AUTOSAR XML (schema 4-1-3)
standard types defined: boolean, uint8
package /UAES/ASW/CompuMethods
  compu method CM_boolean: 0=FALSE, 1=TRUE
package /UAES/ASW/DataConstrs
  range DC_boolean: raw 0..1
  range DC_uint8: raw 0..255
package /UAES/ASW/DataTypeMappingSets
  data type mapping set DTMS_Lock_ComCnvTx
package /UAES/ASW/PortInterfaces
  58 x sender receiver interface:
    ComTx_bLCK_ExterSwOpenFillerCapReq: invalidation-policy{data-element=ComTx_bLCK_ExterSwOpenFillerCapReq/Val, handle-invalid=DONT-INVALIDATE}
      data Val: sw-calibration-access=READ-ONLY, type=boolean
    ComTx_bLCK_FillerCapASt: invalidation-policy{data-element=ComTx_bLCK_FillerCapASt/Val, handle-invalid=DONT-INVALIDATE}
      data Val: sw-calibration-access=READ-ONLY, type=boolean
    ComTx_bLCK_FillerCapBSt: invalidation-policy{data-element=ComTx_bLCK_FillerCapBSt/Val, handle-invalid=DONT-INVALIDATE}
      data Val: sw-calibration-access=READ-ONLY, type=boolean
    ComTx_bLCK_RearLeftChildSaftyLockSt: invalidation-policy{data-element=ComTx_bLCK_RearLeftChildSaftyLockSt/Val, handle-invalid=DONT-INVALIDATE}
      data Val: sw-calibration-access=READ-ONLY, type=boolean
    ComTx_bLCK_RearLeftDoorAjarSt: invalidation-policy{data-element=ComTx_bLCK_RearLeftDoorAjarSt/Val, handle-invalid=DONT-INVALIDATE}
      data Val: sw-calibration-access=READ-ONLY, type=boolean
    ComTx_bLCK_RearLeftDoorLockSt: invalidation-policy{data-element=ComTx_bLCK_RearLeftDoorLockSt/Val, handle-invalid=DONT-INVALIDATE}
      data Val: sw-calibration-access=READ-ONLY, type=boolean
    ComTx_bLCK_RearLeftDoorOpenSt: invalidation-policy{data-element=ComTx_bLCK_RearLeftDoorOpenSt/Val, handle-invalid=DONT-INVALIDATE}
      data Val: sw-calibration-access=READ-ONLY, type=boolean
    ComTx_bLCK_RearLeftPowerReleaseFailedRemind: invalidation-policy{data-element=ComTx_bLCK_RearLeftPowerReleaseFailedRemind/Val, handle-invalid=DONT-INVALIDATE}
      data Val: sw-calibration-access=READ-ONLY, type=boolean
    ComTx_bLCK_RearRightChildSaftyLockSt: invalidation-policy{data-element=ComTx_bLCK_RearRightChildSaftyLockSt/Val, handle-invalid=DONT-INVALIDATE}
      data Val: sw-calibration-access=READ-ONLY, type=boolean
    ComTx_bLCK_RearRightDoorAjarSt: invalidation-policy{data-element=ComTx_bLCK_RearRightDoorAjarSt/Val, handle-invalid=DONT-INVALIDATE}
      data Val: sw-calibration-access=READ-ONLY, type=boolean
    ComTx_bLCK_RearRightDoorLockSt: invalidation-policy{data-element=ComTx_bLCK_RearRightDoorLockSt/Val, handle-invalid=DONT-INVALIDATE}
      data Val: sw-calibration-access=READ-ONLY, type=boolean
    ComTx_bLCK_RearRightDoorOpenSt: invalidation-policy{data-element=ComTx_bLCK_RearRightDoorOpenSt/Val, handle-invalid=DONT-INVALIDATE}
      data Val: sw-calibration-access=READ-ONLY, type=boolean
    ComTx_bLCK_RearRightPowerReleaseFailedRemind: invalidation-policy{data-element=ComTx_bLCK_RearRightPowerReleaseFailedRemind/Val, handle-invalid=DONT-INVALIDATE}
      data Val: sw-calibration-access=READ-ONLY, type=boolean
    ComTx_bLCK_TrunkAjarSt: invalidation-policy{data-element=ComTx_bLCK_TrunkAjarSt/Val, handle-invalid=DONT-INVALIDATE}
      data Val: sw-calibration-access=READ-ONLY, type=boolean
    ComTx_bUINM_RearLeftPowerReleaseFaultSt: invalidation-policy{data-element=ComTx_bUINM_RearLeftPowerReleaseFaultSt/Val, handle-invalid=DONT-INVALIDATE}
      data Val: sw-calibration-access=READ-ONLY, type=boolean
    ComTx_bUINM_RearLeftPowerReleaseReq: invalidation-policy{data-element=ComTx_bUINM_RearLeftPowerReleaseReq/Val, handle-invalid=DONT-INVALIDATE}
      data Val: sw-calibration-access=READ-ONLY, type=boolean
    ComTx_bUINM_RearRightPowerReleaseFaultSt: invalidation-policy{data-element=ComTx_bUINM_RearRightPowerReleaseFaultSt/Val, handle-invalid=DONT-INVALIDATE}
      data Val: sw-calibration-access=READ-ONLY, type=boolean
    ComTx_bUINM_RearRightPowerReleaseReq: invalidation-policy{data-element=ComTx_bUINM_RearRightPowerReleaseReq/Val, handle-invalid=DONT-INVALIDATE}
      data Val: sw-calibration-access=READ-ONLY, type=boolean
    ComTx_u8LCK_FillerCapAction: invalidation-policy{data-element=ComTx_u8LCK_FillerCapAction/Val, handle-invalid=DONT-INVALIDATE}
      data Val: sw-calibration-access=READ-ONLY, type=uint8
    ComTx_u8LCK_FillerCapLock_AAction: invalidation-policy{data-element=ComTx_u8LCK_FillerCapLock_AAction/Val, handle-invalid=DONT-INVALIDATE}
      data Val: sw-calibration-access=READ-ONLY, type=uint8
    ComTx_u8LCK_FillerCapLock_BAction: invalidation-policy{data-element=ComTx_u8LCK_FillerCapLock_BAction/Val, handle-invalid=DONT-INVALIDATE}
      data Val: sw-calibration-access=READ-ONLY, type=uint8
    ComTx_u8LCK_PowerFillerCapAngle: invalidation-policy{data-element=ComTx_u8LCK_PowerFillerCapAngle/Val, handle-invalid=DONT-INVALIDATE}
      data Val: sw-calibration-access=READ-ONLY, type=uint8
    ComTx_u8LCK_RearLeftChildSaftyLockAction: invalidation-policy{data-element=ComTx_u8LCK_RearLeftChildSaftyLockAction/Val, handle-invalid=DONT-INVALIDATE}
      data Val: sw-calibration-access=READ-ONLY, type=uint8
    ComTx_u8LCK_RearLeftDoorLockAction: invalidation-policy{data-element=ComTx_u8LCK_RearLeftDoorLockAction/Val, handle-invalid=DONT-INVALIDATE}
      data Val: sw-calibration-access=READ-ONLY, type=uint8
    ComTx_u8LCK_RearLeftPowerDoorAction: invalidation-policy{data-element=ComTx_u8LCK_RearLeftPowerDoorAction/Val, handle-invalid=DONT-INVALIDATE}
      data Val: sw-calibration-access=READ-ONLY, type=uint8
    ComTx_u8LCK_RearRightChildSaftyLockAction: invalidation-policy{data-element=ComTx_u8LCK_RearRightChildSaftyLockAction/Val, handle-invalid=DONT-INVALIDATE}
      data Val: sw-calibration-access=READ-ONLY, type=uint8
    ComTx_u8LCK_RearRightDoorLockAction: invalidation-policy{data-element=ComTx_u8LCK_RearRightDoorLockAction/Val, handle-invalid=DONT-INVALIDATE}
      data Val: sw-calibration-access=READ-ONLY, type=uint8
    ComTx_u8LCK_RearRightPowerDoorAction: invalidation-policy{data-element=ComTx_u8LCK_RearRightPowerDoorAction/Val, handle-invalid=DONT-INVALIDATE}
      data Val: sw-calibration-access=READ-ONLY, type=uint8
    ComTx_u8LCK_TrunkLockAction: invalidation-policy{data-element=ComTx_u8LCK_TrunkLockAction/Val, handle-invalid=DONT-INVALIDATE}
      data Val: sw-calibration-access=READ-ONLY, type=uint8
    gLOC_bLCK_ExterSwOpenFillerCapReq: invalidation-policy{data-element=gLOC_bLCK_ExterSwOpenFillerCapReq/Val, handle-invalid=DONT-INVALIDATE}
      data Val: sw-calibration-access=READ-ONLY, type=boolean
    gLOC_bLCK_RearLeftChildSaftyLockSt: invalidation-policy{data-element=gLOC_bLCK_RearLeftChildSaftyLockSt/Val, handle-invalid=DONT-INVALIDATE}
      data Val: sw-calibration-access=READ-ONLY, type=boolean
    gLOC_bLCK_RearLeftDoorAjarSt: invalidation-policy{data-element=gLOC_bLCK_RearLeftDoorAjarSt/Val, handle-invalid=DONT-INVALIDATE}
      data Val: sw-calibration-access=READ-ONLY, type=boolean
    gLOC_bLCK_RearLeftDoorLockSt: invalidation-policy{data-element=gLOC_bLCK_RearLeftDoorLockSt/Val, handle-invalid=DONT-INVALIDATE}
      data Val: sw-calibration-access=READ-ONLY, type=boolean
    gLOC_bLCK_RearLeftDoorOpenSt: invalidation-policy{data-element=gLOC_bLCK_RearLeftDoorOpenSt/Val, handle-invalid=DONT-INVALIDATE}
      data Val: sw-calibration-access=READ-ONLY, type=boolean
    gLOC_bLCK_RearRightChildSaftyLockSt: invalidation-policy{data-element=gLOC_bLCK_RearRightChildSaftyLockSt/Val, handle-invalid=DONT-INVALIDATE}
      data Val: sw-calibration-access=READ-ONLY, type=boolean
    gLOC_bLCK_RearRightDoorAjarSt: invalidation-policy{data-element=gLOC_bLCK_RearRightDoorAjarSt/Val, handle-invalid=DONT-INVALIDATE}
      data Val: sw-calibration-access=READ-ONLY, type=boolean
    gLOC_bLCK_RearRightDoorLockSt: invalidation-policy{data-element=gLOC_bLCK_RearRightDoorLockSt/Val, handle-invalid=DONT-INVALIDATE}
      data Val: sw-calibration-access=READ-ONLY, type=boolean
    gLOC_bLCK_RearRightDoorOpenSt: invalidation-policy{data-element=gLOC_bLCK_RearRightDoorOpenSt/Val, handle-invalid=DONT-INVALIDATE}
      data Val: sw-calibration-access=READ-ONLY, type=boolean
    gLOC_bLCK_TrunkAjarSt: invalidation-policy{data-element=gLOC_bLCK_TrunkAjarSt/Val, handle-invalid=DONT-INVALIDATE}
      data Val: sw-calibration-access=READ-ONLY, type=boolean
    gLOC_bUINM_RearLeftPowerReleaseReq: invalidation-policy{data-element=gLOC_bUINM_RearLeftPowerReleaseReq/Val, handle-invalid=DONT-INVALIDATE}
      data Val: sw-calibration-access=READ-ONLY, type=boolean
    gLOC_bUINM_RearRightPowerReleaseReq: invalidation-policy{data-element=gLOC_bUINM_RearRightPowerReleaseReq/Val, handle-invalid=DONT-INVALIDATE}
      data Val: sw-calibration-access=READ-ONLY, type=boolean
    gLOC_u8LCK_FillerCapAction: invalidation-policy{data-element=gLOC_u8LCK_FillerCapAction/Val, handle-invalid=DONT-INVALIDATE}
      data Val: sw-calibration-access=READ-ONLY, type=uint8
    gLOC_u8LCK_FillerCapAngle: invalidation-policy{data-element=gLOC_u8LCK_FillerCapAngle/Val, handle-invalid=DONT-INVALIDATE}
      data Val: sw-calibration-access=READ-ONLY, type=uint8
    gLOC_u8LCK_FillerCapLock_AAction: invalidation-policy{data-element=gLOC_u8LCK_FillerCapLock_AAction/Val, handle-invalid=DONT-INVALIDATE}
      data Val: sw-calibration-access=READ-ONLY, type=uint8
    gLOC_u8LCK_FillerCapLock_BAction: invalidation-policy{data-element=gLOC_u8LCK_FillerCapLock_BAction/Val, handle-invalid=DONT-INVALIDATE}
      data Val: sw-calibration-access=READ-ONLY, type=uint8
    gLOC_u8LCK_RearLeftChildSaftyLockAction: invalidation-policy{data-element=gLOC_u8LCK_RearLeftChildSaftyLockAction/Val, handle-invalid=DONT-INVALIDATE}
      data Val: sw-calibration-access=READ-ONLY, type=uint8
    gLOC_u8LCK_RearLeftDoorLockAction: invalidation-policy{data-element=gLOC_u8LCK_RearLeftDoorLockAction/Val, handle-invalid=DONT-INVALIDATE}
      data Val: sw-calibration-access=READ-ONLY, type=uint8
    gLOC_u8LCK_RearLeftPowerDoorAction: invalidation-policy{data-element=gLOC_u8LCK_RearLeftPowerDoorAction/Val, handle-invalid=DONT-INVALIDATE}
      data Val: sw-calibration-access=READ-ONLY, type=uint8
    gLOC_u8LCK_RearRightChildSaftyLockAction: invalidation-policy{data-element=gLOC_u8LCK_RearRightChildSaftyLockAction/Val, handle-invalid=DONT-INVALIDATE}
      data Val: sw-calibration-access=READ-ONLY, type=uint8
    gLOC_u8LCK_RearRightDoorLockAction: invalidation-policy{data-element=gLOC_u8LCK_RearRightDoorLockAction/Val, handle-invalid=DONT-INVALIDATE}
      data Val: sw-calibration-access=READ-ONLY, type=uint8
    gLOC_u8LCK_RearRightPowerDoorAction: invalidation-policy{data-element=gLOC_u8LCK_RearRightPowerDoorAction/Val, handle-invalid=DONT-INVALIDATE}
      data Val: sw-calibration-access=READ-ONLY, type=uint8
    gLOC_u8LCK_TrunkLockAction: invalidation-policy{data-element=gLOC_u8LCK_TrunkLockAction/Val, handle-invalid=DONT-INVALIDATE}
      data Val: sw-calibration-access=READ-ONLY, type=uint8
    gLock_bLCK_FillerCapASt: invalidation-policy{data-element=gLock_bLCK_FillerCapASt/Val, handle-invalid=DONT-INVALIDATE}
      data Val: sw-calibration-access=READ-ONLY, type=boolean
    gLock_bLCK_FillerCapBSt: invalidation-policy{data-element=gLock_bLCK_FillerCapBSt/Val, handle-invalid=DONT-INVALIDATE}
      data Val: sw-calibration-access=READ-ONLY, type=boolean
    gLock_bLCK_RearLeftPowerReleaseFailedRemind: invalidation-policy{data-element=gLock_bLCK_RearLeftPowerReleaseFailedRemind/Val, handle-invalid=DONT-INVALIDATE}
      data Val: sw-calibration-access=READ-ONLY, type=boolean
    gLock_bLCK_RearRightPowerReleaseFailedRemind: invalidation-policy{data-element=gLock_bLCK_RearRightPowerReleaseFailedRemind/Val, handle-invalid=DONT-INVALIDATE}
      data Val: sw-calibration-access=READ-ONLY, type=boolean
    gLock_bUINM_RearLeftPowerReleaseFaultSt: invalidation-policy{data-element=gLock_bUINM_RearLeftPowerReleaseFaultSt/Val, handle-invalid=DONT-INVALIDATE}
      data Val: sw-calibration-access=READ-ONLY, type=boolean
    gLock_bUINM_RearRightPowerReleaseFaultSt: invalidation-policy{data-element=gLock_bUINM_RearRightPowerReleaseFaultSt/Val, handle-invalid=DONT-INVALIDATE}
      data Val: sw-calibration-access=READ-ONLY, type=boolean
package /UAES/ASW/SwComponentTypes
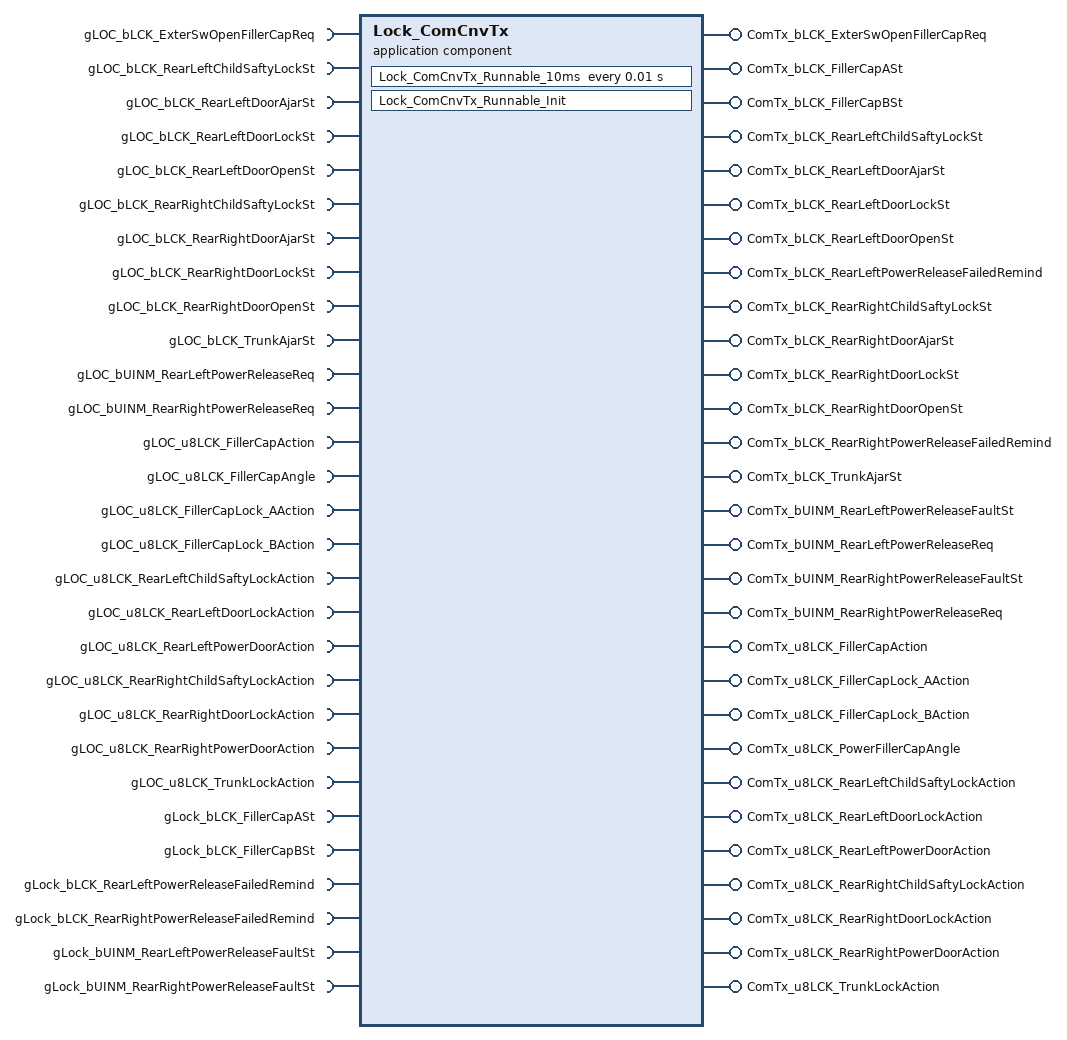
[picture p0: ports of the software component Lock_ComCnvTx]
  application sw component type Lock_ComCnvTx
    29 x provide port:
      ComTx_bLCK_ExterSwOpenFillerCapReq: nonqueued-sender-com-spec{data-element=ComTx_bLCK_ExterSwOpenFillerCapReq/Val, init-value=0}, provided-interface=ComTx_bLCK_ExterSwOpenFillerCapReq
      ComTx_bLCK_FillerCapASt: nonqueued-sender-com-spec{data-element=ComTx_bLCK_FillerCapASt/Val, init-value=0}, provided-interface=ComTx_bLCK_FillerCapASt
      ComTx_bLCK_FillerCapBSt: nonqueued-sender-com-spec{data-element=ComTx_bLCK_FillerCapBSt/Val, init-value=0}, provided-interface=ComTx_bLCK_FillerCapBSt
      ComTx_bLCK_RearLeftChildSaftyLockSt: nonqueued-sender-com-spec{data-element=ComTx_bLCK_RearLeftChildSaftyLockSt/Val, init-value=0}, provided-interface=ComTx_bLCK_RearLeftChildSaftyLockSt
      ComTx_bLCK_RearLeftDoorAjarSt: nonqueued-sender-com-spec{data-element=ComTx_bLCK_RearLeftDoorAjarSt/Val, init-value=0}, provided-interface=ComTx_bLCK_RearLeftDoorAjarSt
      ComTx_bLCK_RearLeftDoorLockSt: nonqueued-sender-com-spec{data-element=ComTx_bLCK_RearLeftDoorLockSt/Val, init-value=0}, provided-interface=ComTx_bLCK_RearLeftDoorLockSt
      ComTx_bLCK_RearLeftDoorOpenSt: nonqueued-sender-com-spec{data-element=ComTx_bLCK_RearLeftDoorOpenSt/Val, init-value=0}, provided-interface=ComTx_bLCK_RearLeftDoorOpenSt
      ComTx_bLCK_RearLeftPowerReleaseFailedRemind: nonqueued-sender-com-spec{data-element=ComTx_bLCK_RearLeftPowerReleaseFailedRemind/Val, init-value=0}, provided-interface=ComTx_bLCK_RearLeftPowerReleaseFailedRemind
      ComTx_bLCK_RearRightChildSaftyLockSt: nonqueued-sender-com-spec{data-element=ComTx_bLCK_RearRightChildSaftyLockSt/Val, init-value=0}, provided-interface=ComTx_bLCK_RearRightChildSaftyLockSt
      ComTx_bLCK_RearRightDoorAjarSt: nonqueued-sender-com-spec{data-element=ComTx_bLCK_RearRightDoorAjarSt/Val, init-value=0}, provided-interface=ComTx_bLCK_RearRightDoorAjarSt
      ComTx_bLCK_RearRightDoorLockSt: nonqueued-sender-com-spec{data-element=ComTx_bLCK_RearRightDoorLockSt/Val, init-value=0}, provided-interface=ComTx_bLCK_RearRightDoorLockSt
      ComTx_bLCK_RearRightDoorOpenSt: nonqueued-sender-com-spec{data-element=ComTx_bLCK_RearRightDoorOpenSt/Val, init-value=0}, provided-interface=ComTx_bLCK_RearRightDoorOpenSt
      ComTx_bLCK_RearRightPowerReleaseFailedRemind: nonqueued-sender-com-spec{data-element=ComTx_bLCK_RearRightPowerReleaseFailedRemind/Val, init-value=0}, provided-interface=ComTx_bLCK_RearRightPowerReleaseFailedRemind
      ComTx_bLCK_TrunkAjarSt: nonqueued-sender-com-spec{data-element=ComTx_bLCK_TrunkAjarSt/Val, init-value=0}, provided-interface=ComTx_bLCK_TrunkAjarSt
      ComTx_bUINM_RearLeftPowerReleaseFaultSt: nonqueued-sender-com-spec{data-element=ComTx_bUINM_RearLeftPowerReleaseFaultSt/Val, init-value=0}, provided-interface=ComTx_bUINM_RearLeftPowerReleaseFaultSt
      ComTx_bUINM_RearLeftPowerReleaseReq: nonqueued-sender-com-spec{data-element=ComTx_bUINM_RearLeftPowerReleaseReq/Val, init-value=0}, provided-interface=ComTx_bUINM_RearLeftPowerReleaseReq
      ComTx_bUINM_RearRightPowerReleaseFaultSt: nonqueued-sender-com-spec{data-element=ComTx_bUINM_RearRightPowerReleaseFaultSt/Val, init-value=0}, provided-interface=ComTx_bUINM_RearRightPowerReleaseFaultSt
      ComTx_bUINM_RearRightPowerReleaseReq: nonqueued-sender-com-spec{data-element=ComTx_bUINM_RearRightPowerReleaseReq/Val, init-value=0}, provided-interface=ComTx_bUINM_RearRightPowerReleaseReq
      ComTx_u8LCK_FillerCapAction: nonqueued-sender-com-spec{data-element=ComTx_u8LCK_FillerCapAction/Val, init-value=0}, provided-interface=ComTx_u8LCK_FillerCapAction
      ComTx_u8LCK_FillerCapLock_AAction: nonqueued-sender-com-spec{data-element=ComTx_u8LCK_FillerCapLock_AAction/Val, init-value=0}, provided-interface=ComTx_u8LCK_FillerCapLock_AAction
      ComTx_u8LCK_FillerCapLock_BAction: nonqueued-sender-com-spec{data-element=ComTx_u8LCK_FillerCapLock_BAction/Val, init-value=0}, provided-interface=ComTx_u8LCK_FillerCapLock_BAction
      ComTx_u8LCK_PowerFillerCapAngle: nonqueued-sender-com-spec{data-element=ComTx_u8LCK_PowerFillerCapAngle/Val, init-value=0}, provided-interface=ComTx_u8LCK_PowerFillerCapAngle
      ComTx_u8LCK_RearLeftChildSaftyLockAction: nonqueued-sender-com-spec{data-element=ComTx_u8LCK_RearLeftChildSaftyLockAction/Val, init-value=0}, provided-interface=ComTx_u8LCK_RearLeftChildSaftyLockAction
      ComTx_u8LCK_RearLeftDoorLockAction: nonqueued-sender-com-spec{data-element=ComTx_u8LCK_RearLeftDoorLockAction/Val, init-value=0}, provided-interface=ComTx_u8LCK_RearLeftDoorLockAction
      ComTx_u8LCK_RearLeftPowerDoorAction: nonqueued-sender-com-spec{data-element=ComTx_u8LCK_RearLeftPowerDoorAction/Val, init-value=0}, provided-interface=ComTx_u8LCK_RearLeftPowerDoorAction
      ComTx_u8LCK_RearRightChildSaftyLockAction: nonqueued-sender-com-spec{data-element=ComTx_u8LCK_RearRightChildSaftyLockAction/Val, init-value=0}, provided-interface=ComTx_u8LCK_RearRightChildSaftyLockAction
      ComTx_u8LCK_RearRightDoorLockAction: nonqueued-sender-com-spec{data-element=ComTx_u8LCK_RearRightDoorLockAction/Val, init-value=0}, provided-interface=ComTx_u8LCK_RearRightDoorLockAction
      ComTx_u8LCK_RearRightPowerDoorAction: nonqueued-sender-com-spec{data-element=ComTx_u8LCK_RearRightPowerDoorAction/Val, init-value=0}, provided-interface=ComTx_u8LCK_RearRightPowerDoorAction
      ComTx_u8LCK_TrunkLockAction: nonqueued-sender-com-spec{data-element=ComTx_u8LCK_TrunkLockAction/Val, init-value=0}, provided-interface=ComTx_u8LCK_TrunkLockAction
    29 x require port:
      gLOC_bLCK_ExterSwOpenFillerCapReq: nonqueued-receiver-com-spec{data-element=gLOC_bLCK_ExterSwOpenFillerCapReq/Val, filter=data-filter-type=ALWAYS, init-value=0}, required-interface=gLOC_bLCK_ExterSwOpenFillerCapReq
      gLOC_bLCK_RearLeftChildSaftyLockSt: nonqueued-receiver-com-spec{data-element=gLOC_bLCK_RearLeftChildSaftyLockSt/Val, filter=data-filter-type=ALWAYS, init-value=0}, required-interface=gLOC_bLCK_RearLeftChildSaftyLockSt
      gLOC_bLCK_RearLeftDoorAjarSt: nonqueued-receiver-com-spec{data-element=gLOC_bLCK_RearLeftDoorAjarSt/Val, filter=data-filter-type=ALWAYS, init-value=0}, required-interface=gLOC_bLCK_RearLeftDoorAjarSt
      gLOC_bLCK_RearLeftDoorLockSt: nonqueued-receiver-com-spec{data-element=gLOC_bLCK_RearLeftDoorLockSt/Val, filter=data-filter-type=ALWAYS, init-value=0}, required-interface=gLOC_bLCK_RearLeftDoorLockSt
      gLOC_bLCK_RearLeftDoorOpenSt: nonqueued-receiver-com-spec{data-element=gLOC_bLCK_RearLeftDoorOpenSt/Val, filter=data-filter-type=ALWAYS, init-value=0}, required-interface=gLOC_bLCK_RearLeftDoorOpenSt
      gLOC_bLCK_RearRightChildSaftyLockSt: nonqueued-receiver-com-spec{data-element=gLOC_bLCK_RearRightChildSaftyLockSt/Val, filter=data-filter-type=ALWAYS, init-value=0}, required-interface=gLOC_bLCK_RearRightChildSaftyLockSt
      gLOC_bLCK_RearRightDoorAjarSt: nonqueued-receiver-com-spec{data-element=gLOC_bLCK_RearRightDoorAjarSt/Val, filter=data-filter-type=ALWAYS, init-value=0}, required-interface=gLOC_bLCK_RearRightDoorAjarSt
      gLOC_bLCK_RearRightDoorLockSt: nonqueued-receiver-com-spec{data-element=gLOC_bLCK_RearRightDoorLockSt/Val, filter=data-filter-type=ALWAYS, init-value=0}, required-interface=gLOC_bLCK_RearRightDoorLockSt
      gLOC_bLCK_RearRightDoorOpenSt: nonqueued-receiver-com-spec{data-element=gLOC_bLCK_RearRightDoorOpenSt/Val, filter=data-filter-type=ALWAYS, init-value=0}, required-interface=gLOC_bLCK_RearRightDoorOpenSt
      gLOC_bLCK_TrunkAjarSt: nonqueued-receiver-com-spec{data-element=gLOC_bLCK_TrunkAjarSt/Val, filter=data-filter-type=ALWAYS, init-value=0}, required-interface=gLOC_bLCK_TrunkAjarSt
      gLOC_bUINM_RearLeftPowerReleaseReq: nonqueued-receiver-com-spec{data-element=gLOC_bUINM_RearLeftPowerReleaseReq/Val, filter=data-filter-type=ALWAYS, init-value=0}, required-interface=gLOC_bUINM_RearLeftPowerReleaseReq
      gLOC_bUINM_RearRightPowerReleaseReq: nonqueued-receiver-com-spec{data-element=gLOC_bUINM_RearRightPowerReleaseReq/Val, filter=data-filter-type=ALWAYS, init-value=0}, required-interface=gLOC_bUINM_RearRightPowerReleaseReq
      gLOC_u8LCK_FillerCapAction: nonqueued-receiver-com-spec{data-element=gLOC_u8LCK_FillerCapAction/Val, filter=data-filter-type=ALWAYS, init-value=0}, required-interface=gLOC_u8LCK_FillerCapAction
      gLOC_u8LCK_FillerCapAngle: nonqueued-receiver-com-spec{data-element=gLOC_u8LCK_FillerCapAngle/Val, filter=data-filter-type=ALWAYS, init-value=0}, required-interface=gLOC_u8LCK_FillerCapAngle
      gLOC_u8LCK_FillerCapLock_AAction: nonqueued-receiver-com-spec{data-element=gLOC_u8LCK_FillerCapLock_AAction/Val, filter=data-filter-type=ALWAYS, init-value=0}, required-interface=gLOC_u8LCK_FillerCapLock_AAction
      gLOC_u8LCK_FillerCapLock_BAction: nonqueued-receiver-com-spec{data-element=gLOC_u8LCK_FillerCapLock_BAction/Val, filter=data-filter-type=ALWAYS, init-value=0}, required-interface=gLOC_u8LCK_FillerCapLock_BAction
      gLOC_u8LCK_RearLeftChildSaftyLockAction: nonqueued-receiver-com-spec{data-element=gLOC_u8LCK_RearLeftChildSaftyLockAction/Val, filter=data-filter-type=ALWAYS, init-value=0}, required-interface=gLOC_u8LCK_RearLeftChildSaftyLockAction
      gLOC_u8LCK_RearLeftDoorLockAction: nonqueued-receiver-com-spec{data-element=gLOC_u8LCK_RearLeftDoorLockAction/Val, filter=data-filter-type=ALWAYS, init-value=0}, required-interface=gLOC_u8LCK_RearLeftDoorLockAction
      gLOC_u8LCK_RearLeftPowerDoorAction: nonqueued-receiver-com-spec{data-element=gLOC_u8LCK_RearLeftPowerDoorAction/Val, filter=data-filter-type=ALWAYS, init-value=0}, required-interface=gLOC_u8LCK_RearLeftPowerDoorAction
      gLOC_u8LCK_RearRightChildSaftyLockAction: nonqueued-receiver-com-spec{data-element=gLOC_u8LCK_RearRightChildSaftyLockAction/Val, filter=data-filter-type=ALWAYS, init-value=0}, required-interface=gLOC_u8LCK_RearRightChildSaftyLockAction
      gLOC_u8LCK_RearRightDoorLockAction: nonqueued-receiver-com-spec{data-element=gLOC_u8LCK_RearRightDoorLockAction/Val, filter=data-filter-type=ALWAYS, init-value=0}, required-interface=gLOC_u8LCK_RearRightDoorLockAction
      gLOC_u8LCK_RearRightPowerDoorAction: nonqueued-receiver-com-spec{data-element=gLOC_u8LCK_RearRightPowerDoorAction/Val, filter=data-filter-type=ALWAYS, init-value=0}, required-interface=gLOC_u8LCK_RearRightPowerDoorAction
      gLOC_u8LCK_TrunkLockAction: nonqueued-receiver-com-spec{data-element=gLOC_u8LCK_TrunkLockAction/Val, filter=data-filter-type=ALWAYS, init-value=0}, required-interface=gLOC_u8LCK_TrunkLockAction
      gLock_bLCK_FillerCapASt: nonqueued-receiver-com-spec{data-element=gLock_bLCK_FillerCapASt/Val, filter=data-filter-type=ALWAYS, init-value=0}, required-interface=gLock_bLCK_FillerCapASt
      gLock_bLCK_FillerCapBSt: nonqueued-receiver-com-spec{data-element=gLock_bLCK_FillerCapBSt/Val, filter=data-filter-type=ALWAYS, init-value=0}, required-interface=gLock_bLCK_FillerCapBSt
      gLock_bLCK_RearLeftPowerReleaseFailedRemind: nonqueued-receiver-com-spec{data-element=gLock_bLCK_RearLeftPowerReleaseFailedRemind/Val, filter=data-filter-type=ALWAYS, init-value=0}, required-interface=gLock_bLCK_RearLeftPowerReleaseFailedRemind
      gLock_bLCK_RearRightPowerReleaseFailedRemind: nonqueued-receiver-com-spec{data-element=gLock_bLCK_RearRightPowerReleaseFailedRemind/Val, filter=data-filter-type=ALWAYS, init-value=0}, required-interface=gLock_bLCK_RearRightPowerReleaseFailedRemind
      gLock_bUINM_RearLeftPowerReleaseFaultSt: nonqueued-receiver-com-spec{data-element=gLock_bUINM_RearLeftPowerReleaseFaultSt/Val, filter=data-filter-type=ALWAYS, init-value=0}, required-interface=gLock_bUINM_RearLeftPowerReleaseFaultSt
      gLock_bUINM_RearRightPowerReleaseFaultSt: nonqueued-receiver-com-spec{data-element=gLock_bUINM_RearRightPowerReleaseFaultSt/Val, filter=data-filter-type=ALWAYS, init-value=0}, required-interface=gLock_bUINM_RearRightPowerReleaseFaultSt
    behavior Lock_ComCnvTx_InternalBehavior: data-type-mapping=DTMS_Lock_ComCnvTx
      timing event TMT_Lock_ComCnvTx_Runnable_10ms: start-on-event=Lock_ComCnvTx_Runnable_10ms, period=0.01
      init event Lock_ComCnvTx_InitEvent: start-on-event=Lock_ComCnvTx_Runnable_Init
      runnable Lock_ComCnvTx_Runnable_10ms
        data-receive-point-by-arguments:
          29 x access:
            REC_gLOC_bLCK_ExterSwOpenFillerCapReq_Val: accessed-variable=gLOC_bLCK_ExterSwOpenFillerCapReq.Val
            REC_gLOC_bLCK_RearLeftChildSaftyLockSt_Val: accessed-variable=gLOC_bLCK_RearLeftChildSaftyLockSt.Val
            REC_gLOC_bLCK_RearLeftDoorAjarSt_Val: accessed-variable=gLOC_bLCK_RearLeftDoorAjarSt.Val
            REC_gLOC_bLCK_RearLeftDoorLockSt_Val: accessed-variable=gLOC_bLCK_RearLeftDoorLockSt.Val
            REC_gLOC_bLCK_RearLeftDoorOpenSt_Val: accessed-variable=gLOC_bLCK_RearLeftDoorOpenSt.Val
            REC_gLOC_bLCK_RearRightChildSaftyLockSt_Val: accessed-variable=gLOC_bLCK_RearRightChildSaftyLockSt.Val
            REC_gLOC_bLCK_RearRightDoorAjarSt_Val: accessed-variable=gLOC_bLCK_RearRightDoorAjarSt.Val
            REC_gLOC_bLCK_RearRightDoorLockSt_Val: accessed-variable=gLOC_bLCK_RearRightDoorLockSt.Val
            REC_gLOC_bLCK_RearRightDoorOpenSt_Val: accessed-variable=gLOC_bLCK_RearRightDoorOpenSt.Val
            REC_gLOC_bLCK_TrunkAjarSt_Val: accessed-variable=gLOC_bLCK_TrunkAjarSt.Val
            REC_gLOC_bUINM_RearLeftPowerReleaseReq_Val: accessed-variable=gLOC_bUINM_RearLeftPowerReleaseReq.Val
            REC_gLOC_bUINM_RearRightPowerReleaseReq_Val: accessed-variable=gLOC_bUINM_RearRightPowerReleaseReq.Val
            REC_gLOC_u8LCK_FillerCapAction_Val: accessed-variable=gLOC_u8LCK_FillerCapAction.Val
            REC_gLOC_u8LCK_FillerCapAngle_Val: accessed-variable=gLOC_u8LCK_FillerCapAngle.Val
            REC_gLOC_u8LCK_FillerCapLock_AAction_Val: accessed-variable=gLOC_u8LCK_FillerCapLock_AAction.Val
            REC_gLOC_u8LCK_FillerCapLock_BAction_Val: accessed-variable=gLOC_u8LCK_FillerCapLock_BAction.Val
            REC_gLOC_u8LCK_RearLeftChildSaftyLockAction_Val: accessed-variable=gLOC_u8LCK_RearLeftChildSaftyLockAction.Val
            REC_gLOC_u8LCK_RearLeftDoorLockAction_Val: accessed-variable=gLOC_u8LCK_RearLeftDoorLockAction.Val
            REC_gLOC_u8LCK_RearLeftPowerDoorAction_Val: accessed-variable=gLOC_u8LCK_RearLeftPowerDoorAction.Val
            REC_gLOC_u8LCK_RearRightChildSaftyLockAction_Val: accessed-variable=gLOC_u8LCK_RearRightChildSaftyLockAction.Val
            REC_gLOC_u8LCK_RearRightDoorLockAction_Val: accessed-variable=gLOC_u8LCK_RearRightDoorLockAction.Val
            REC_gLOC_u8LCK_RearRightPowerDoorAction_Val: accessed-variable=gLOC_u8LCK_RearRightPowerDoorAction.Val
            REC_gLOC_u8LCK_TrunkLockAction_Val: accessed-variable=gLOC_u8LCK_TrunkLockAction.Val
            REC_gLock_bLCK_FillerCapASt_Val: accessed-variable=gLock_bLCK_FillerCapASt.Val
            REC_gLock_bLCK_FillerCapBSt_Val: accessed-variable=gLock_bLCK_FillerCapBSt.Val
            REC_gLock_bLCK_RearLeftPowerReleaseFailedRemind_Val: accessed-variable=gLock_bLCK_RearLeftPowerReleaseFailedRemind.Val
            REC_gLock_bLCK_RearRightPowerReleaseFailedRemind_Val: accessed-variable=gLock_bLCK_RearRightPowerReleaseFailedRemind.Val
            REC_gLock_bUINM_RearLeftPowerReleaseFaultSt_Val: accessed-variable=gLock_bUINM_RearLeftPowerReleaseFaultSt.Val
            REC_gLock_bUINM_RearRightPowerReleaseFaultSt_Val: accessed-variable=gLock_bUINM_RearRightPowerReleaseFaultSt.Val
        data-send-points:
          29 x access:
            SEND_ComTx_bLCK_ExterSwOpenFillerCapReq_Val: accessed-variable=ComTx_bLCK_ExterSwOpenFillerCapReq.Val
            SEND_ComTx_bLCK_FillerCapASt_Val: accessed-variable=ComTx_bLCK_FillerCapASt.Val
            SEND_ComTx_bLCK_FillerCapBSt_Val: accessed-variable=ComTx_bLCK_FillerCapBSt.Val
            SEND_ComTx_bLCK_RearLeftChildSaftyLockSt_Val: accessed-variable=ComTx_bLCK_RearLeftChildSaftyLockSt.Val
            SEND_ComTx_bLCK_RearLeftDoorAjarSt_Val: accessed-variable=ComTx_bLCK_RearLeftDoorAjarSt.Val
            SEND_ComTx_bLCK_RearLeftDoorLockSt_Val: accessed-variable=ComTx_bLCK_RearLeftDoorLockSt.Val
            SEND_ComTx_bLCK_RearLeftDoorOpenSt_Val: accessed-variable=ComTx_bLCK_RearLeftDoorOpenSt.Val
            SEND_ComTx_bLCK_RearLeftPowerReleaseFailedRemind_Val: accessed-variable=ComTx_bLCK_RearLeftPowerReleaseFailedRemind.Val
            SEND_ComTx_bLCK_RearRightChildSaftyLockSt_Val: accessed-variable=ComTx_bLCK_RearRightChildSaftyLockSt.Val
            SEND_ComTx_bLCK_RearRightDoorAjarSt_Val: accessed-variable=ComTx_bLCK_RearRightDoorAjarSt.Val
            SEND_ComTx_bLCK_RearRightDoorLockSt_Val: accessed-variable=ComTx_bLCK_RearRightDoorLockSt.Val
            SEND_ComTx_bLCK_RearRightDoorOpenSt_Val: accessed-variable=ComTx_bLCK_RearRightDoorOpenSt.Val
            SEND_ComTx_bLCK_RearRightPowerReleaseFailedRemind_Val: accessed-variable=ComTx_bLCK_RearRightPowerReleaseFailedRemind.Val
            SEND_ComTx_bLCK_TrunkAjarSt_Val: accessed-variable=ComTx_bLCK_TrunkAjarSt.Val
            SEND_ComTx_bUINM_RearLeftPowerReleaseFaultSt_Val: accessed-variable=ComTx_bUINM_RearLeftPowerReleaseFaultSt.Val
            SEND_ComTx_bUINM_RearLeftPowerReleaseReq_Val: accessed-variable=ComTx_bUINM_RearLeftPowerReleaseReq.Val
            SEND_ComTx_bUINM_RearRightPowerReleaseFaultSt_Val: accessed-variable=ComTx_bUINM_RearRightPowerReleaseFaultSt.Val
            SEND_ComTx_bUINM_RearRightPowerReleaseReq_Val: accessed-variable=ComTx_bUINM_RearRightPowerReleaseReq.Val
            SEND_ComTx_u8LCK_FillerCapAction_Val: accessed-variable=ComTx_u8LCK_FillerCapAction.Val
            SEND_ComTx_u8LCK_FillerCapLock_AAction_Val: accessed-variable=ComTx_u8LCK_FillerCapLock_AAction.Val
            SEND_ComTx_u8LCK_FillerCapLock_BAction_Val: accessed-variable=ComTx_u8LCK_FillerCapLock_BAction.Val
            SEND_ComTx_u8LCK_PowerFillerCapAngle_Val: accessed-variable=ComTx_u8LCK_PowerFillerCapAngle.Val
            SEND_ComTx_u8LCK_RearLeftChildSaftyLockAction_Val: accessed-variable=ComTx_u8LCK_RearLeftChildSaftyLockAction.Val
            SEND_ComTx_u8LCK_RearLeftDoorLockAction_Val: accessed-variable=ComTx_u8LCK_RearLeftDoorLockAction.Val
            SEND_ComTx_u8LCK_RearLeftPowerDoorAction_Val: accessed-variable=ComTx_u8LCK_RearLeftPowerDoorAction.Val
            SEND_ComTx_u8LCK_RearRightChildSaftyLockAction_Val: accessed-variable=ComTx_u8LCK_RearRightChildSaftyLockAction.Val
            SEND_ComTx_u8LCK_RearRightDoorLockAction_Val: accessed-variable=ComTx_u8LCK_RearRightDoorLockAction.Val
            SEND_ComTx_u8LCK_RearRightPowerDoorAction_Val: accessed-variable=ComTx_u8LCK_RearRightPowerDoorAction.Val
            SEND_ComTx_u8LCK_TrunkLockAction_Val: accessed-variable=ComTx_u8LCK_TrunkLockAction.Val
      runnable Lock_ComCnvTx_Runnable_Init
  swc implementation Lock_ComCnvTx_Implementation: behavior=Lock_ComCnvTx_InternalBehavior
    code-descriptors:
      code Default: artifact-descriptors=autosar-engineering-object={short-label=Default, category=SWSRC}
package /UAES/ASW/Units
  unit NoUnit: factor-si-to-unit=1, offset-si-to-unit=0
